# NUC100DN_v1 register map
File version: 1.0
Registers are 32-bit, read-write, reset 0x0 unless marked. A register's access mark holds for its fields unless they carry their own. Offsets are from the block's base; [hi:lo] are bit positions.

## RTC — RTC Register Map
Base 0x40008000
0x00 INIR — RTC Initiation Register
  [31:0] INIR — RTC Initiation. Read return current RTC active status. A write of 0xa5eb1357 will make RTC leaving reset state. When RTC block is powered on, RTC is at reset state. User has to write a number 0x a5eb1357 to INIR register to make RTC leaving reset state. Once the INIR is written as 0xa5eb1357, the RTC will be in normal active state permanently.
    0=RTC is at reset state; 1=RTC is at normal active state
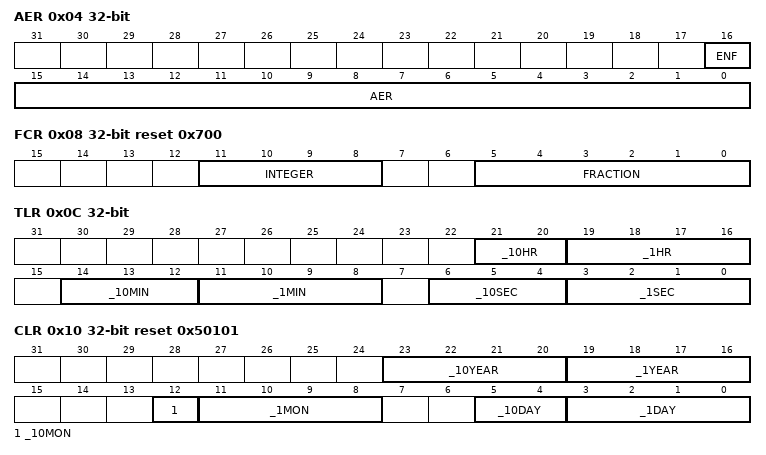
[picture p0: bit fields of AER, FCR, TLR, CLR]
0x04 AER — RTC Access Enable Register
  [16] ENF ro — RTC Register Access Enable Flag (Read Only). This bit indicates the RTC Access Enable status. This bit will be set after AER[15:0] register is loaded with a 0xA965, and will be cleared automatically after 1024 RTC clocks.
    0=RTC register read/write access Disabled; 1=RTC register read/write access Enabled
  [15:0] AER wo — RTC Register Access Enable Password (Write Only). Writing 0xA965 to this register will enable RTC registers read/write access and keep 1024 RTC clocks.
0x08 FCR reset 0x700 — RTC Frequency Compensation Register
  [11:8] INTEGER — Integer Part. Digit in FCR must be expressed as hexadecimal number. Refer to 6.12.4.4 for the examples.
  [5:0] FRACTION — Fraction Part. Note: Digit in FCR must be expressed as hexadecimal number. Refer to 6.12.4.4 for the examples.
0x0C TLR — RTC Time Loading Register
  [21:20] _10HR — 10-Hour Time Digit (0~2)
  [19:16] _1HR — 1-Hour Time Digit (0~9)
  [14:12] _10MIN — 10-Min Time Digit (0~5)
  [11:8] _1MIN — 1-Min Time Digit (0~9)
  [6:4] _10SEC — 10-Sec Time Digit (0~5)
  [3:0] _1SEC — 1-Sec Time Digit (0~9)
0x10 CLR reset 0x50101 — RTC Calendar Loading Register
  [23:20] _10YEAR — 10-Year Calendar Digit (0~9)
  [19:16] _1YEAR — 1-Year Calendar Digit (0~9)
  [12] _10MON — 10-Month Calendar Digit (0~1)
  [11:8] _1MON — 1-Month Calendar Digit (0~9)
  [5:4] _10DAY — 10-Day Calendar Digit (0~3)
  [3:0] _1DAY — 1-Day Calendar Digit (0~9)
0x14 TSSR reset 0x1 — RTC Time Scale Selection Register
  [0] _24H_12H — 24-hour / 12-hour Time Scale Selection. It indicates that TLR and TAR counter are in 24-hour time scale or 12-hour time scale
    0=Selected as 12-hour time scale with AM and PM indication (high bit of 10HR field in TLR and TAR); 1=Selected as 24-hour time scale
0x18 DWR reset 0x6 — RTC Day of the Week Register
  [2:0] DWR — Day of the Week Register. The field indicates day of the week from 0 to 6 to represent Sunday to Saturday respectively.
    0=Sunday; 1=Monday; 2=Tuesday; 3=Wednesday; 4=Thursday; 5=Friday; 6=Saturday
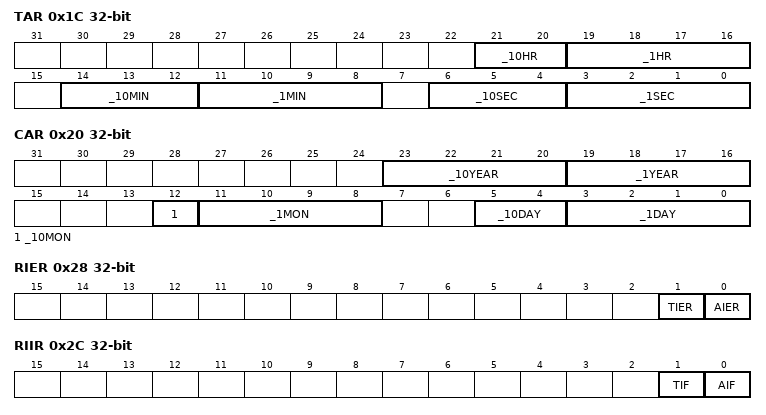
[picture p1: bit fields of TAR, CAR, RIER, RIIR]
0x1C TAR — RTC Time Alarm Register
  [21:20] _10HR — 10-Hour Time Digit of Alarm Setting (0~2)
  [19:16] _1HR — 1-Hour Time Digit of Alarm Setting (0~9)
  [14:12] _10MIN — 10-Min Time Digit of Alarm Setting (0~5)
  [11:8] _1MIN — 1-Min Time Digit of Alarm Setting (0~9)
  [6:4] _10SEC — 10-Sec Time Digit of Alarm Setting (0~5)
  [3:0] _1SEC — 1-Sec Time Digit of Alarm Setting (0~9)
0x20 CAR — RTC Calendar Alarm Register
  [23:20] _10YEAR — 10-Year Calendar Digit of Alarm Setting (0~9)
  [19:16] _1YEAR — 1-Year Calendar Digit of Alarm Setting (0~9)
  [12] _10MON — 10-Month Calendar Digit of Alarm Setting (0~1)
  [11:8] _1MON — 1-Month Calendar Digit of Alarm Setting (0~9)
  [5:4] _10DAY — 10-Day Calendar Digit of Alarm Setting (0~3)
  [3:0] _1DAY — 1-Day Calendar Digit of Alarm Setting (0~9)
0x24 LIR ro — RTC Leap Year Indication Register
  [0] LIR — Leap Year Indication Register (Read Only). This bit indicates RTC current year is a leap year or not.
    0=This year is not a leap year; 1=This year is a leap year
0x28 RIER — RTC Interrupt Enable Register
  [1] TIER — Time Tick Interrupt Enable Bit. This bit is used to enable/disable RTC Time Tick Interrupt, and generate an interrupt signal if TIF (RIIR [1] RTC Time Tick Interrupt Flag) is set to 1. Note: This bit will also trigger a wake-up event while system runs in Idle/Power-Down mode and RTC Time Tick Interrupt signal generated.
    0=RTC Time Tick Interrupt Disabled; 1=RTC Time Tick Interrupt Enabled
  [0] AIER — Alarm Interrupt Enable Bit. This bit is used to enable/disable RTC Alarm Interrupt, and generate an interrupt signal if AIF (RIIR [0] RTC Alarm Interrupt Flag) is set to 1. Note: This bit will also trigger a wake-up event while system runs in Idle/Power-Down mode and RTC Alarm Interrupt signal generated.
    0=RTC Alarm Interrupt Disabled; 1=RTC Alarm Interrupt Enabled
0x2C RIIR — RTC Interrupt Indication Register
  [1] TIF — RTC Time Tick Interrupt Flag. When RTC Time Tick time-out happened, this bit will be set to 1 and an interrupt signal will be generated if TIER bit is set to 1. Note: Software can clear this bit by writing 1 to it.
  [0] AIF — RTC Alarm Interrupt Flag. When RTC real time counters TLR and CLR reach the alarm time setting registers TAR and CAR, this bit will be set to 1 and an interrupt signal will be generated if AIER bit is set to 1. Note: Software can clear this bit by writing 1 to it.
0x30 TTR — RTC Time Tick Register
  [2:0] TTR — Time Tick Register. The RTC time tick period for Periodic Time Tick Interrupt request.
    0=Time tick is 1 second; 1=Time tick is 1/2 second; 2=Time tick is 1/4 second; 3=Time tick is 1/8 second; 4=Time tick is 1/16 second; 5=Time tick is 1/32 second; 6=Time tick is 1/64 second; 7=Time tick is 1/28 second
